VERSION ""

NS_ :

BS_:

BU_: XXX

BO_ 380 ENGINE: 8 XXX
 SG_ NEW_SIGNAL_2 : 61|2@0+ (1,0) [0|3] "" XXX
 SG_ ENGINE_RPM : 23|16@0+ (1,0) [0|255] "" XXX

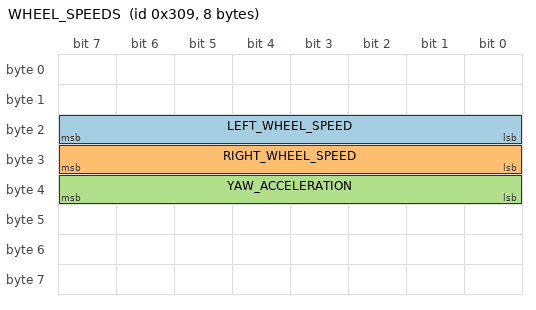
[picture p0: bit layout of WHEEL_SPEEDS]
BO_ 777 WHEEL_SPEEDS: 8 XXX
 SG_ LEFT_WHEEL_SPEED : 23|8@0+ (1,0) [0|255] "" XXX
 SG_ RIGHT_WHEEL_SPEED : 31|8@0+ (1,0) [0|255] "" XXX
 SG_ YAW_ACCELERATION : 39|8@0+ (1,0) [0|255] "" XXX

BO_ 398 NEW_MSG_2: 8 XXX
 SG_ NEW_SIGNAL_1 : 14|7@0+ (1,0) [0|255] "" XXX
 SG_ NEW_SIGNAL_2 : 19|4@0+ (1,0) [0|255] "" XXX

BO_ 1029 GAUGE_LIGHTS: 8 XXX
 SG_ SEATBELT_LIGHT_ON : 18|1@0+ (1,0) [0|255] "" XXX
 SG_ HANDBRAKE_LIGHT_ON : 21|1@0+ (1,0) [0|3] "" XXX
